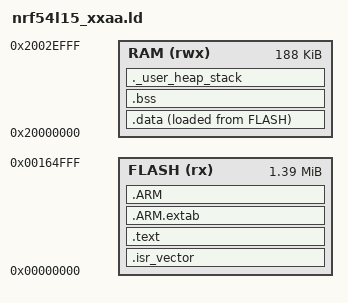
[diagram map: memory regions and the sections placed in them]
/* SPDX-License-Identifier: AGPL-3.0-or-later */
/* Bare-metal linker script for Nordic nRF54L15 Application Core (Cortex-M33) */

MEMORY
{
    FLASH (rx)  : ORIGIN = 0x00000000, LENGTH = 1428K
    RAM   (rwx) : ORIGIN = 0x20000000, LENGTH = 188K
}

ENTRY(Reset_Handler)

_estack = ORIGIN(RAM) + LENGTH(RAM);

SECTIONS
{
    .isr_vector :
    {
        . = ALIGN(1024);
        KEEP(*(.isr_vector))
        . = ALIGN(4);
    } > FLASH

    .text :
    {
        . = ALIGN(4);
        *(.text)
        *(.text*)
        *(.rodata)
        *(.rodata*)
        KEEP(*(.init))
        KEEP(*(.fini))
        . = ALIGN(4);
        _etext = .;
    } > FLASH

    .ARM.extab :
    {
        *(.ARM.extab* .gnu.linkonce.armextab.*)
    } > FLASH

    .ARM :
    {
        __exidx_start = .;
        *(.ARM.exidx*)
        __exidx_end = .;
    } > FLASH

    _sidata = LOADADDR(.data);

    .data :
    {
        . = ALIGN(4);
        _sdata = .;
        *(.data)
        *(.data*)
        *(.ramfunc)
        *(.ramfunc*)
        . = ALIGN(4);
        _edata = .;
    } > RAM AT > FLASH

    .bss :
    {
        . = ALIGN(4);
        _sbss = .;
        __bss_start__ = _sbss;
        *(.bss)
        *(.bss*)
        *(COMMON)
        . = ALIGN(4);
        _ebss = .;
        __bss_end__ = _ebss;
    } > RAM

    ._user_heap_stack :
    {
        . = ALIGN(8);
        PROVIDE(end = .);
        PROVIDE(_end = .);
        . = . + 0x4000;
        . = ALIGN(8);
    } > RAM
}
